# NUC1263AE register map
File version: 1.0
Registers are 32-bit, read-write, reset 0x0 unless marked. A register's access mark holds for its fields unless they carry their own. Offsets are from the block's base; [hi:lo] are bit positions; {n}, {i} and the like mark numbered series; 'fields as' and 'values as' point back to an identical list.

## PDMA — PDMA Register Map
Base 0x50008000
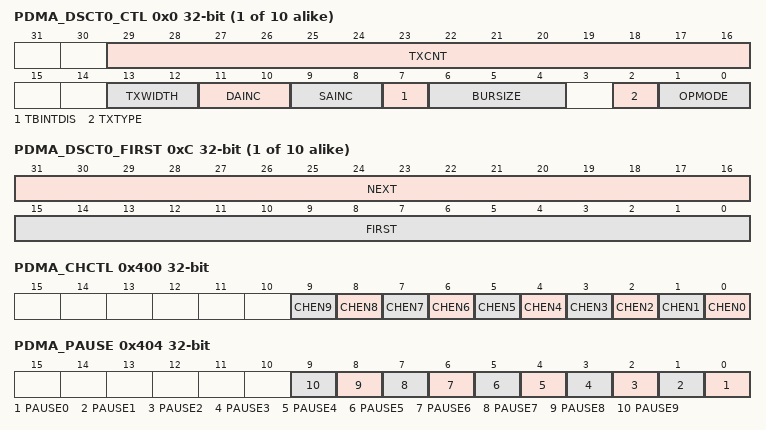
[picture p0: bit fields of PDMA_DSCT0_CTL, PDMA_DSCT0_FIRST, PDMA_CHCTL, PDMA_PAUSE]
{0x0+0x10*i} PDMA_DSCT{i}_CTL reset not defined (i=0..9) — Descriptor Table Control Register of PDMA Channel n
  [29:16] TXCNT — Transfer Count. The TXCNT represents the required number of PDMA transfer, the real transfer count is (TXCNT + 1); The maximum transfer count is 16384, every transfer may be byte, half-word or word that is dependent on TXWIDTH field. Note: When PDMA finishes each transfer data, this field will be decreased immediately.
  [13:12] TXWIDTH — Transfer Width Selection. This field is used for transfer width. Note: The PDMA transfer source address (PDMA_DSCT_SA) and PDMA transfer destination address (PDMA_DSCT_DA) should be alignment under the TXWIDTH selection. For example, if source address is 0x2000_0202, but TXWIDTH is word transfer, the source address is not word alignment. The source address is aligned when TXWIDTH is byte or half-word transfer.
    0=One byte (8 bit) is transferred for every operation; 1=One half-word (16 bit) is transferred for every operation; 2=One word (32-bit) is transferred for every operation
  [11:10] DAINC — Destination Address Increment. This field is used to set the destination address increment size.
    3=No increment (fixed address)
  [9:8] SAINC — Source Address Increment. This Field Is Used To Set The Source Address Increment Size.
    3=No Increment (Fixed Address)
  [7] TBINTDIS — Table Interrupt Disable Bit. This field can be used to decide whether to enable table interrupt or not. If the TBINTDIS bit is enabled when PDMA controller finishes transfer task, it will not generates transfer done interrupt. Note: If this bit set to '1', the TEMPTYF will not be set.
    0=Table interrupt Enabled; 1=Table interrupt Disabled
  [6:4] BURSIZE — Burst Size. This field is used for peripheral to determine the burst size or used to determine the re-arbitration size. Note: This field is only useful in burst transfer type.
    0=128 Transfers; 1=64 Transfers; 2=32 Transfers; 3=16 Transfers; 4=8 Transfers; 5=4 Transfers; 6=2 Transfers; 7=1 Transfers
  [2] TXTYPE — Transfer Type
    0=Burst transfer type; 1=Single transfer type
  [1:0] OPMODE — PDMA Operation Mode Selection. Note: Before filling transfer task in the Descriptor Table, user must check if the descriptor table is complete.
    0=Idle state: Channel is stopped or this table is complete. When PDMA finishes channel table task, OPMODE will be cleared to idle state automatically; 1=Basic mode: The descriptor table only has one task. When this task is finished, the TDIF(PDMA_INTSTS[1]) will be asserted; 2=Scatter-Gather mode: When operating in this mode, user must give the first descriptor table address in PDMA_DSCT_FIRST register; the PDMA controller will ignore this task, then load the next task to execute
{0x4+0x10*i} PDMA_DSCT{i}_SA reset not defined (i=0..9) — Source Address Register of PDMA Channel n
  [31:0] SA — PDMA Transfer Source Address Register. This field indicates a 32-bit source address of PDMA controller.
{0x8+0x10*i} PDMA_DSCT{i}_DA reset not defined (i=0..9) — Destination Address Register of PDMA Channel n
  [31:0] DA — PDMA Transfer Destination Address Register. This field indicates a 32-bit destination address of PDMA controller.
{0xC+0x10*i} PDMA_DSCT{i}_FIRST reset not defined (i=0..9) — First Scatter-gather Descriptor Table Offset of PDMA Channel n
  [31:16] NEXT — PDMA Next Descriptor Table Offset. This field indicates the offset of next descriptor table address in system memory. Note: write operation is useless in this field.
  [15:0] FIRST — PDMA First Descriptor Table Offset. This field indicates the offset of the first descriptor table address in system memory. Write Operation: If the system memory based address is 0x2000_0000 (PDMA_SCATBA), and the first descriptor table is started from 0x2000_0100, then this field must be filled with 0x0100. Read Operation: When operating in scatter-gather mode, the last two bits FIRST[1:0] will become reserved. Note 1: The first descriptor table address must be word boundary. Note 2: Before filled transfer task in the descriptor table, user must check if the descriptor table is complete.
{0xA0+4i} PDMA_CURSCAT{i} ro reset not defined (i=0..9) — Current Scatter-gather Descriptor Table Address of PDMA Channel n
  [31:0] CURADDR — PDMA Current Description Address Register (Read Only). This field indicates a 32-bit current external description address of PDMA controller. Note: This field is read only and only used for Scatter-Gather mode to indicate the current external description address.
0x400 PDMA_CHCTL — PDMA Channel Control Register
  [all] fields
    0=PDMA channel [n] Disabled; 1=PDMA channel [n] Enabled
  [n] CHEN{n} (n=0..9) — PDMA Channel n Enable Bit. Set this bit to 1 to enable PDMAn operation. Channel cannot be active if it is not set as enabled. Note: Set PDMA_PAUSE or PDMA_RESET register will also clear this bit.
0x404 PDMA_PAUSE wo — PDMA Transfer Pause Control Register
  [all] fields
    0=No effect; 1=Pause PDMA channel n transfer
  [n] PAUSE{n} (n=0..9) — PDMA Channel n Transfer Pause Control Register (Write Only)
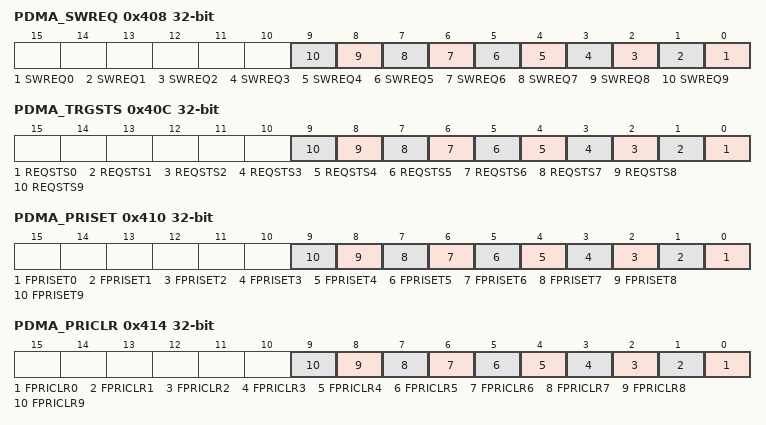
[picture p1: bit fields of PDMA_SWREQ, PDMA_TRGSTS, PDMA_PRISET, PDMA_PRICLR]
0x408 PDMA_SWREQ wo — PDMA Software Request Register
  [all] fields
    0=No effect; 1=Generate a software request
  [n] SWREQ{n} (n=0..9) — PDMA Channel n Software Request Register (Write Only). Set this bit to 1 to generate a software request to PDMA [n]. Note 1: User can read PDMA_TRGSTS register to know which channel is on active. Active flag may be triggered by software request or peripheral request. Note 2: If user does not enable corresponding PDMA channel, the software request will be ignored.
0x40C PDMA_TRGSTS ro — PDMA Channel Request Status Register
  [all] fields
    0=PDMA Channel n has no request; 1=PDMA Channel n has a request
  [n] REQSTS{n} (n=0..9) — PDMA Channel n Request Status (Read Only). This flag indicates whether channel[n] have a request or not, no matter request from software or peripheral. When the PDMA controller finishes channel transfer, this bit will be cleared automatically. Note: If user pauses or resets each PDMA transfer by setting PDMA_PAUSE or PDMA_RESET register respectively, this bit will be cleared automatically after finishing current transfer.
0x410 PDMA_PRISET — PDMA Fixed Priority Setting Register
  [all] fields
    0=No effect. Corresponding PDMA channel is round-robin priority; 1=Set PDMA channel [n] to fixed priority channel. Corresponding PDMA channel is fixed priority
  [n] FPRISET{n} (n=0..9) — PDMA Channel n Fixed Priority Setting Register. Set this bit to 1 to enable fixed priority level. The fixed priority channel has higher priority than round-robin priority channel. If multiple channels are set as the same priority, the higher number of channels have higher priority. Write Operation: Note: This field only set to fixed priority, clear fixed priority use PDMA_PRICLR register.
0x414 PDMA_PRICLR wo — PDMA Fixed Priority Clear Register
  [all] fields
    0=No effect; 1=Clear PDMA channel [n] fixed priority setting
  [n] FPRICLR{n} (n=0..9) — PDMA Channel n Fixed Priority Clear Register (Write Only). Set this bit to 1 to clear fixed priority level. Note: User can read PDMA_PRISET register to know the channel priority.
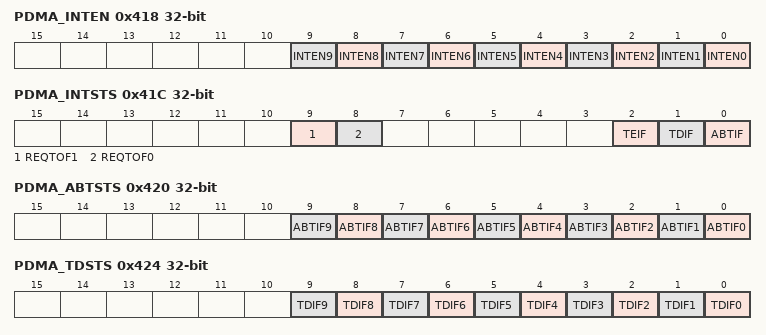
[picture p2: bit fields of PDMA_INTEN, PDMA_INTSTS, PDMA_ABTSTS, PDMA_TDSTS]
0x418 PDMA_INTEN — PDMA Interrupt Enable Register
  [all] fields
    0=PDMA channel n interrupt Disabled; 1=PDMA channel n interrupt Enabled
  [n] INTEN{n} (n=0..9) — PDMA Channel n Interrupt Enable Register. This field is used for enabling PDMA channel[n] interrupt.
0x41C PDMA_INTSTS — PDMA Interrupt Status Register
  [9] REQTOF1 — PDMA Channel n Request Time-out Flag. This flag indicates that PDMA controller has waited peripheral request for a period defined by PDMA_TOCn, user can write 1 to clear these bits.
    0=No request time-out; 1=Peripheral request time-out
  [8] REQTOF0 — PDMA Channel n Request Time-out Flag. This flag indicates that PDMA controller has waited peripheral request for a period defined by PDMA_TOCn, user can write 1 to clear these bits.
    0=No request time-out; 1=Peripheral request time-out
  [2] TEIF ro — Table Empty Interrupt Flag (Read Only). This bit indicates PDMA channel scatter-gather table is empty. User can read PDMA_SCATSTS register to indicate which channel scatter-gather table is empty.
    0=PDMA channel scatter-gather table is not empty; 1=PDMA channel scatter-gather table is empty
  [1] TDIF ro — Transfer Done Interrupt Flag (Read Only). This bit indicates that PDMA controller has finished transmission; User can read PDMA_TDSTS register to indicate which channel finished transfer.
    0=Not finished yet; 1=PDMA channel has finished transmission
  [0] ABTIF ro — PDMA Read/Write Target Abort Interrupt Flag (Read Only). This bit indicates that PDMA has target abort error; Software can read PDMA_ABTSTS register to find which channel has target abort error.
    0=No AHB bus ERROR response received; 1=AHB bus ERROR response received
0x420 PDMA_ABTSTS — PDMA Channel Read/Write Target Abort Flag Register
  [all] fields
    0=No AHB bus ERROR response received when channel n transfer; 1=AHB bus ERROR response received when channel n transfer
  [n] ABTIF{n} (n=0..9) — PDMA Channel n Read/Write Target Abort Interrupt Status Flag. This bit indicates which PDMA controller has target abort error; User can write 1 to clear these bits.
0x424 PDMA_TDSTS — PDMA Channel Transfer Done Flag Register
  [all] fields
    0=PDMA channel transfer has not finished; 1=PDMA channel has finished transmission
  [n] TDIF{n} (n=0..9) — PDMA Channel n Transfer Done Flag Register. This bit indicates whether PDMA controller channel transfer has been finished or not, user can write 1 to clear these bits.
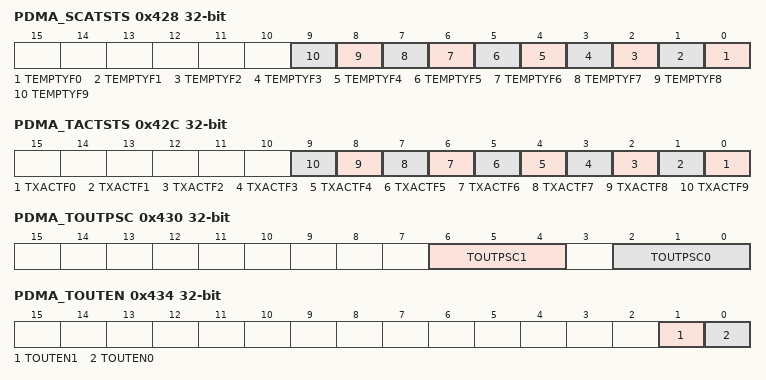
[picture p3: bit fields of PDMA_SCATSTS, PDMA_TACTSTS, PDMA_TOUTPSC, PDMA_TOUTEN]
0x428 PDMA_SCATSTS — PDMA Scatter-gather Table Empty Status Register
  [all] fields
    0=PDMA channel scatter-gather table is not empty; 1=PDMA channel scatter-gather table is empty and PDMA SWREQ has be set
  [n] TEMPTYF{n} (n=0..9) — Table Empty Flag Register. T This bit indicates which PDMA channel table is empty when channel has a request, no matter request from software or peripheral, but operation mode of channel descriptor table is idle state, or channel has finished current transfer and next table operation mode is idle state for PDMA Scatter-Gather mode. User can write 1 to clear these bits.
0x42C PDMA_TACTSTS ro — PDMA Transfer Active Flag Register
  [all] fields
    0=PDMA channel is not finished; 1=PDMA channel is active
  [n] TXACTF{n} (n=0..9) — PDMA Channel n Transfer on Active Flag Register (Read Only). This bit indicates which PDMA channel is in active.
0x430 PDMA_TOUTPSC — PDMA Time-out Prescaler Register
  [6:4] TOUTPSC1 — PDMA Channel 1 Time-out Clock Source Prescaler Bits
    0=PDMA channel 1 time-out clock source is HCLK/28; 1=PDMA channel 1 time-out clock source is HCLK/29; {v}=PDMA channel 1 time-out clock source is HCLK/{v+208} (v=2..7)
  [2:0] TOUTPSC0 — PDMA Channel 0 Time-out Clock Source Prescaler Bits
    0=PDMA channel 0 time-out clock source is HCLK/28; 1=PDMA channel 0 time-out clock source is HCLK/29; {v}=PDMA channel 0 time-out clock source is HCLK/{v+208} (v=2..7)
0x434 PDMA_TOUTEN — PDMA Time-out Enable Register
  [1] TOUTEN1 — PDMA Channel n Time-out Enable Bit
    0=PDMA Channel n time-out function Disabled; 1=PDMA Channel n time-out function Enabled
  [0] TOUTEN0 — PDMA Channel n Time-out Enable Bit
    values as TOUTEN1
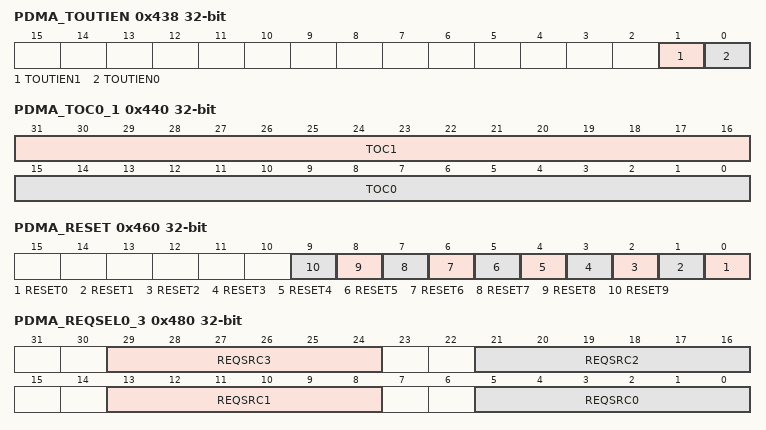
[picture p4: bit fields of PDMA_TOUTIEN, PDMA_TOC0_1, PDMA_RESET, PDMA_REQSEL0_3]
0x438 PDMA_TOUTIEN — PDMA Time-out Interrupt Enable Register
  [1] TOUTIEN1 — PDMA Channel n Time-out Interrupt Enable Bit
    0=PDMA Channel n time-out interrupt Disabled; 1=PDMA Channel n time-out interrupt Enabled
  [0] TOUTIEN0 — PDMA Channel n Time-out Interrupt Enable Bit
    values as TOUTIEN1
0x43C PDMA_SCATBA reset 0x20000000 — PDMA Scatter-gather Descriptor Table Base Address Register
  [31:16] SCATBA — PDMA Scatter-gather Descriptor Table Address Register. In Scatter-Gather mode, this is the base address for calculating the next link - list address. The next link address equation is. Note: Only useful in Scatter-Gather mode.
0x440 PDMA_TOC0_1 — PDMA Channel 0 and Channel 1 Time-out Counter Register
  [31:16] TOC1 — Time-out Counter for Channel 1. This controls the period of time-out function for channel 1. The calculation unit is based on TOUTPSC1 (PDMA_TOUTPSC[5:3]) clock. The example of time-out period can refer TOC0 bit description.
  [15:0] TOC0 — Time-out Counter for Channel 0. This controls the period of time-out function for channel 0. The calculation unit is based on TOUTPSC0 (PDMA_TOUTPSC[2:0]) clock.
0x460 PDMA_RESET — PDMA Channel Reset Control Register
  [all] fields
    0=No effect; 1=Reset PDMA channel n
  [n] RESET{n} (n=0..9) — PDMA Channel n Reset Control Register. Note: This bit will be cleared automatically after finishing reset process.
0x480 PDMA_REQSEL0_3 — PDMA Channel 0 to Channel 3 Request Source Select Register
  [29:24] REQSRC3 — Channel 3 Request Source Selection. This filed defines which peripheral is connected to PDMA channel 3. User can configure the peripheral setting by REQSRC3. Note: The channel configuration is the same as REQSRC0 field. Please refer to the explanation of REQSRC0.
  [21:16] REQSRC2 — Channel 2 Request Source Selection. This filed defines which peripheral is connected to PDMA channel 2. User can configure the peripheral setting by REQSRC2. Note: The channel configuration is the same as REQSRC0 field. Please refer to the explanation of REQSRC0.
  [13:8] REQSRC1 — Channel 1 Request Source Selection. This filed defines which peripheral is connected to PDMA channel 1. User can configure the peripheral setting by REQSRC1. Note: The channel configuration is the same as REQSRC0 field. Please refer to the explanation of REQSRC0.
  [5:0] REQSRC0 — Channel 0 Request Source Selection. This filed defines which peripheral is connected to PDMA channel 0. User can configure the peripheral by setting REQSRC0. Note 1: A request source can't assign to two channels at the same time. Note 2: This field is useless when transfer between memory and memory.
    0=Disable PDMA; 4=Channel connects to UART0_TX; 5=Channel connects to UART0_RX; 6=Channel connects to UART1_TX; 7=Channel connects to UART1_RX; 8=Channel connects to UART2_TX; 9=Channel connects to UART2_RX; {v}=Channel connects to DAC_{v-10} TX (v=10..13); 16=Channel connects to SPI0_TX; 17=Channel connects to SPI0_RX; 18=Channel connects to SPI1_TX; 19=Channel connects to SPI1_RX; 20=Channel connects to ADC_RX; 22=Channel connects to I3CS0_TX; 23=Channel connects to I3CS0_RX; 24=Channel connects to I3CS1_TX; 25=Channel connects to I3CS1_RX; 28=Channel connects to I2C0_TX; 29=Channel connects to I2C0_RX; 30=Channel connects to I2C1_TX; 31=Channel connects to I2C1_RX; {v}=Channel connects to TMR{v-32} (v=32..35); {v}=Channel connects to LLSI{v-36} (v=36..41); 46=Channel connects to SPI2_TX; 47=Channel connects to SPI2_RX; 48=Channel connects to I2C2_TX; 49=Channel connects to I2C2_RX
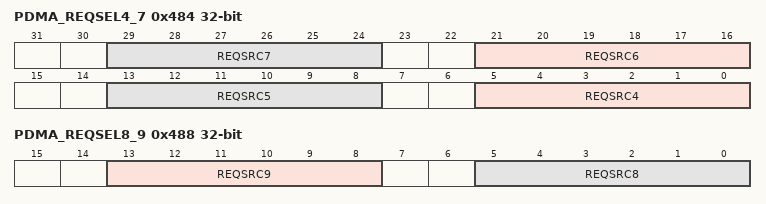
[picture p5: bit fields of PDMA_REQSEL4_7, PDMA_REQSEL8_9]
0x484 PDMA_REQSEL4_7 — PDMA Channel 4 to Channel 7 Request Source Select Register
  [8n-27:8n-32] REQSRC{n} (n=4..7) — Channel {n} Request Source Selection. This filed defines which peripheral is connected to PDMA channel {n}. User can configure the peripheral setting by REQSRC{n}. Note: The channel configuration is the same as REQSRC0 field. Please refer to the explanation of REQSRC0.
0x488 PDMA_REQSEL8_9 — PDMA Channel 8 to Channel 9 Request Source Select Register
  [13:8] REQSRC9 — Channel 9 Request Source Selection. This filed defines which peripheral is connected to PDMA channel 9. User can configure the peripheral setting by REQSRC9. Note: The channel configuration is the same as REQSRC0 field. Please refer to the explanation of REQSRC0.
  [5:0] REQSRC8 — Channel 8 Request Source Selection. This filed defines which peripheral is connected to PDMA channel 8. User can configure the peripheral setting by REQSRC8. Note: The channel configuration is the same as REQSRC0 field. Please refer to the explanation of REQSRC0.
